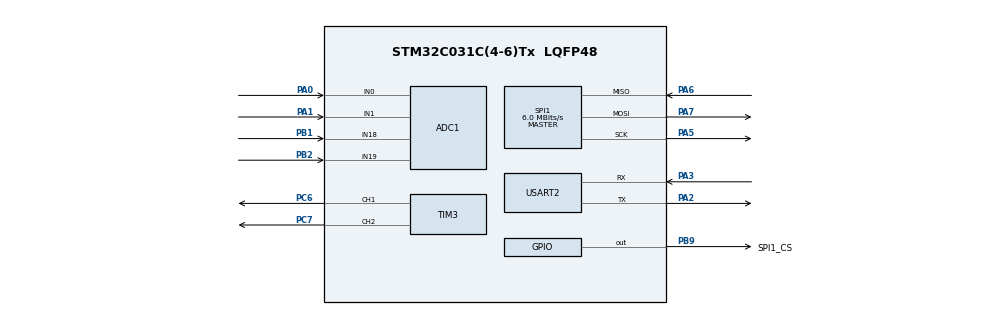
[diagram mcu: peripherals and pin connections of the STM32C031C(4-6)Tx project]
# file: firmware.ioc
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ADC1.NbrOfConversionFlag=0
ADC1.SelectedChannel=ADC_CHANNEL_0|ADC_CHANNEL_1|ADC_CHANNEL_18|ADC_CHANNEL_19
ADC1.master=1
Mcu.Family=STM32C0
Mcu.Name=STM32C031C(4-6)Tx
Mcu.Package=LQFP48
PA0.Mode=IN0
PA0.Signal=ADC1_IN0
PA1.Mode=IN1
PA1.Signal=ADC1_IN1
PA2.Mode=Asynchronous
PA2.Signal=USART2_TX
PA3.Mode=Asynchronous
PA3.Signal=USART2_RX
PA5.Mode=Full_Duplex_Master
PA5.Signal=SPI1_SCK
PA6.Mode=Full_Duplex_Master
PA6.Signal=SPI1_MISO
PA7.Mode=Full_Duplex_Master
PA7.Signal=SPI1_MOSI
PB1.Mode=IN18
PB1.Signal=ADC1_IN18
PB2.Mode=IN19
PB2.Signal=ADC1_IN19
PB9.GPIO_Label=SPI1_CS
PB9.Signal=GPIO_Output
PC6.Signal=S_TIM3_CH1
PC7.Signal=S_TIM3_CH2
ProjectManager.HeapSize=0x200
ProjectManager.StackSize=0x400
ProjectManager.TargetToolchain=Makefile
RCC.ADCFreq_Value=12000000
RCC.AHBFreq_Value=12000000
RCC.CortexFreq_Value=12000000
RCC.EXTERNAL_CLOCK_VALUE=12288000
RCC.HCLKFreq_Value=12000000
RCC.HSE_VALUE=8000000
RCC.HSI_VALUE=48000000
RCC.LSE_VALUE=32768
RCC.SYSCLKFreq_VALUE=12000000
SH.S_TIM3_CH1.0=TIM3_CH1,PWM Generation1 CH1
SH.S_TIM3_CH2.0=TIM3_CH2,PWM Generation2 CH2
SPI1.CalculateBaudRate=6.0 MBits/s
SPI1.Direction=SPI_DIRECTION_2LINES
SPI1.Mode=SPI_MODE_MASTER
SPI1.VirtualType=VM_MASTER
TIM3.Channel-PWM\ Generation1\ CH1=TIM_CHANNEL_1
TIM3.Channel-PWM\ Generation2\ CH2=TIM_CHANNEL_2
USART2.VirtualMode-Asynchronous=VM_ASYNC
board=NUCLEO-C031C6

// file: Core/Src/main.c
/* USER CODE BEGIN Header */
/**
  ******************************************************************************
  * @file           : main.c
  * @brief          : Main program body
  ******************************************************************************
  * @attention
  *
  * Copyright (c) 2026 STMicroelectronics.
  * All rights reserved.
  *
  * This software is licensed under terms that can be found in the LICENSE file
  * in the root directory of this software component.
  * If no LICENSE file comes with this software, it is provided AS-IS.
  *
  ******************************************************************************
  */
/* USER CODE END Header */
#include "main.h"

/* USER CODE BEGIN Includes */
#include "plat_uart.h"
#include "plat_mem.h"
#include "app.h"
/* USER CODE END Includes */

ADC_HandleTypeDef hadc1;

SPI_HandleTypeDef hspi1;

TIM_HandleTypeDef htim3;

UART_HandleTypeDef huart2;

/* USER CODE BEGIN PV */
static app_t app;
/* USER CODE END PV */

void SystemClock_Config(void);
static void MX_GPIO_Init(void);
static void MX_ADC1_Init(void);
static void MX_SPI1_Init(void);
static void MX_TIM3_Init(void);
static void MX_USART2_UART_Init(void);

int main(void)
{

  /* USER CODE BEGIN 1 */
  plat_mem_init();

  /* USER CODE END 1 */

  /* MCU Configuration--------------------------------------------------------*/

  /* Reset of all peripherals, Initializes the Flash interface and the Systick. */
  HAL_Init();

  /* Configure the system clock */
  SystemClock_Config();

  /* Initialize all configured peripherals */
  MX_GPIO_Init();
  MX_ADC1_Init();
  MX_SPI1_Init();
  MX_TIM3_Init();
  MX_USART2_UART_Init();
  /* USER CODE BEGIN 2 */
  static const char banner[] = "Heliostat boot OK\r\n";
  (void)plat_uart_write((const uint8_t *)banner, sizeof banner - 1U);
  app_init(&app);
  (void)app_selftest(&app);
  app_start(&app);
  /* USER CODE END 2 */

  /* Infinite loop */
  while (1)
  {

    /* USER CODE BEGIN 3 */
        app_poll(&app);
  }
  /* USER CODE END 3 */
}

void SystemClock_Config(void)
{
  RCC_OscInitTypeDef RCC_OscInitStruct = {0};
  RCC_ClkInitTypeDef RCC_ClkInitStruct = {0};

  __HAL_FLASH_SET_LATENCY(FLASH_LATENCY_0);

  /** Initializes the RCC Oscillators according to the specified parameters
  * in the RCC_OscInitTypeDef structure.
  */
  RCC_OscInitStruct.OscillatorType = RCC_OSCILLATORTYPE_HSI;
  RCC_OscInitStruct.HSIState = RCC_HSI_ON;
  RCC_OscInitStruct.HSIDiv = RCC_HSI_DIV4;
  RCC_OscInitStruct.HSICalibrationValue = RCC_HSICALIBRATION_DEFAULT;
  if (HAL_RCC_OscConfig(&RCC_OscInitStruct) != HAL_OK)
  {
    Error_Handler();
  }

  /** Initializes the CPU, AHB and APB buses clocks
  */
  RCC_ClkInitStruct.ClockType = RCC_CLOCKTYPE_HCLK|RCC_CLOCKTYPE_SYSCLK
                              |RCC_CLOCKTYPE_PCLK1;
  RCC_ClkInitStruct.SYSCLKSource = RCC_SYSCLKSOURCE_HSI;
  RCC_ClkInitStruct.SYSCLKDivider = RCC_SYSCLK_DIV1;
  RCC_ClkInitStruct.AHBCLKDivider = RCC_HCLK_DIV1;
  RCC_ClkInitStruct.APB1CLKDivider = RCC_APB1_DIV1;

  if (HAL_RCC_ClockConfig(&RCC_ClkInitStruct, FLASH_LATENCY_0) != HAL_OK)
  {
    Error_Handler();
  }
}

static void MX_ADC1_Init(void)
{

  ADC_ChannelConfTypeDef sConfig = {0};

  /** Configure the global features of the ADC (Clock, Resolution, Data Alignment and number of conversion)
  */
  hadc1.Instance = ADC1;
  hadc1.Init.ClockPrescaler = ADC_CLOCK_SYNC_PCLK_DIV1;
  hadc1.Init.Resolution = ADC_RESOLUTION_12B;
  hadc1.Init.DataAlign = ADC_DATAALIGN_RIGHT;
  hadc1.Init.ScanConvMode = ADC_SCAN_SEQ_FIXED;
  hadc1.Init.EOCSelection = ADC_EOC_SINGLE_CONV;
  hadc1.Init.LowPowerAutoWait = DISABLE;
  hadc1.Init.LowPowerAutoPowerOff = DISABLE;
  hadc1.Init.ContinuousConvMode = DISABLE;
  hadc1.Init.NbrOfConversion = 1;
  hadc1.Init.DiscontinuousConvMode = DISABLE;
  hadc1.Init.ExternalTrigConv = ADC_SOFTWARE_START;
  hadc1.Init.ExternalTrigConvEdge = ADC_EXTERNALTRIGCONVEDGE_NONE;
  hadc1.Init.DMAContinuousRequests = DISABLE;
  hadc1.Init.Overrun = ADC_OVR_DATA_PRESERVED;
  hadc1.Init.SamplingTimeCommon1 = ADC_SAMPLETIME_1CYCLE_5;
  hadc1.Init.OversamplingMode = DISABLE;
  hadc1.Init.TriggerFrequencyMode = ADC_TRIGGER_FREQ_HIGH;
  if (HAL_ADC_Init(&hadc1) != HAL_OK)
  {
    Error_Handler();
  }

  /** Configure Regular Channel
  */
  sConfig.Channel = ADC_CHANNEL_0;
  sConfig.Rank = ADC_RANK_CHANNEL_NUMBER;
  if (HAL_ADC_ConfigChannel(&hadc1, &sConfig) != HAL_OK)
  {
    Error_Handler();
  }

  /** Configure Regular Channel
  */
  sConfig.Channel = ADC_CHANNEL_1;
  if (HAL_ADC_ConfigChannel(&hadc1, &sConfig) != HAL_OK)
  {
    Error_Handler();
  }

  /** Configure Regular Channel
  */
  sConfig.Channel = ADC_CHANNEL_18;
  if (HAL_ADC_ConfigChannel(&hadc1, &sConfig) != HAL_OK)
  {
    Error_Handler();
  }

  /** Configure Regular Channel
  */
  sConfig.Channel = ADC_CHANNEL_19;
  if (HAL_ADC_ConfigChannel(&hadc1, &sConfig) != HAL_OK)
  {
    Error_Handler();
  }

}

static void MX_SPI1_Init(void)
{

  /* SPI1 parameter configuration*/
  hspi1.Instance = SPI1;
  hspi1.Init.Mode = SPI_MODE_MASTER;
  hspi1.Init.Direction = SPI_DIRECTION_2LINES;
  hspi1.Init.DataSize = SPI_DATASIZE_8BIT;
  hspi1.Init.CLKPolarity = SPI_POLARITY_LOW;
  hspi1.Init.CLKPhase = SPI_PHASE_1EDGE;
  hspi1.Init.NSS = SPI_NSS_SOFT;
  hspi1.Init.BaudRatePrescaler = SPI_BAUDRATEPRESCALER_2;
  hspi1.Init.FirstBit = SPI_FIRSTBIT_MSB;
  hspi1.Init.TIMode = SPI_TIMODE_DISABLE;
  hspi1.Init.CRCCalculation = SPI_CRCCALCULATION_DISABLE;
  hspi1.Init.CRCPolynomial = 7;
  hspi1.Init.CRCLength = SPI_CRC_LENGTH_DATASIZE;
  hspi1.Init.NSSPMode = SPI_NSS_PULSE_ENABLE;
  if (HAL_SPI_Init(&hspi1) != HAL_OK)
  {
    Error_Handler();
  }

}

static void MX_TIM3_Init(void)
{

  TIM_MasterConfigTypeDef sMasterConfig = {0};
  TIM_OC_InitTypeDef sConfigOC = {0};

  htim3.Instance = TIM3;
  htim3.Init.Prescaler = 0;
  htim3.Init.CounterMode = TIM_COUNTERMODE_UP;
  htim3.Init.Period = 65535;
  htim3.Init.ClockDivision = TIM_CLOCKDIVISION_DIV1;
  htim3.Init.AutoReloadPreload = TIM_AUTORELOAD_PRELOAD_DISABLE;
  if (HAL_TIM_PWM_Init(&htim3) != HAL_OK)
  {
    Error_Handler();
  }
  sMasterConfig.MasterOutputTrigger = TIM_TRGO_RESET;
  sMasterConfig.MasterSlaveMode = TIM_MASTERSLAVEMODE_DISABLE;
  if (HAL_TIMEx_MasterConfigSynchronization(&htim3, &sMasterConfig) != HAL_OK)
  {
    Error_Handler();
  }
  sConfigOC.OCMode = TIM_OCMODE_PWM1;
  sConfigOC.Pulse = 0;
  sConfigOC.OCPolarity = TIM_OCPOLARITY_HIGH;
  sConfigOC.OCFastMode = TIM_OCFAST_DISABLE;
  if (HAL_TIM_PWM_ConfigChannel(&htim3, &sConfigOC, TIM_CHANNEL_1) != HAL_OK)
  {
    Error_Handler();
  }
  if (HAL_TIM_PWM_ConfigChannel(&htim3, &sConfigOC, TIM_CHANNEL_2) != HAL_OK)
  {
    Error_Handler();
  }
  HAL_TIM_MspPostInit(&htim3);

}

static void MX_USART2_UART_Init(void)
{

  huart2.Instance = USART2;
  huart2.Init.BaudRate = 115200;
  huart2.Init.WordLength = UART_WORDLENGTH_8B;
  huart2.Init.StopBits = UART_STOPBITS_1;
  huart2.Init.Parity = UART_PARITY_NONE;
  huart2.Init.Mode = UART_MODE_TX_RX;
  huart2.Init.HwFlowCtl = UART_HWCONTROL_NONE;
  huart2.Init.OverSampling = UART_OVERSAMPLING_16;
  huart2.Init.OneBitSampling = UART_ONE_BIT_SAMPLE_DISABLE;
  huart2.Init.ClockPrescaler = UART_PRESCALER_DIV1;
  huart2.AdvancedInit.AdvFeatureInit = UART_ADVFEATURE_NO_INIT;
  if (HAL_UART_Init(&huart2) != HAL_OK)
  {
    Error_Handler();
  }

}

static void MX_GPIO_Init(void)
{
  GPIO_InitTypeDef GPIO_InitStruct = {0};

  /* GPIO Ports Clock Enable */
  __HAL_RCC_GPIOA_CLK_ENABLE();
  __HAL_RCC_GPIOB_CLK_ENABLE();
  __HAL_RCC_GPIOC_CLK_ENABLE();

  /*Configure GPIO pin Output Level */
  HAL_GPIO_WritePin(SPI1_CS_GPIO_Port, SPI1_CS_Pin, GPIO_PIN_RESET);

  /*Configure GPIO pin : SPI1_CS_Pin */
  GPIO_InitStruct.Pin = SPI1_CS_Pin;
  GPIO_InitStruct.Mode = GPIO_MODE_OUTPUT_PP;
  GPIO_InitStruct.Pull = GPIO_NOPULL;
  GPIO_InitStruct.Speed = GPIO_SPEED_FREQ_LOW;
  HAL_GPIO_Init(SPI1_CS_GPIO_Port, &GPIO_InitStruct);

}

void Error_Handler(void)
{
  __disable_irq();
  while (1)
  {
  }
}
